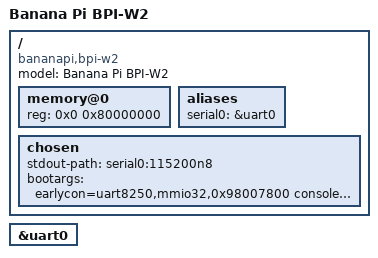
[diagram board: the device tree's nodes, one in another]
/*
 * Copyright (c) 2019 Nicolas Saenz Julienne
 *
 * SPDX-License-Identifier: (GPL-2.0+ OR MIT)
 */

/dts-v1/;

#include "rtd1296.dtsi"

/ {
	compatible = "bananapi,bpi-w2", "realtek,rtd1296";
	model = "Banana Pi BPI-W2";

	memory@0 {
		device_type = "memory";
		reg = <0x0 0x80000000>;
	};

	aliases {
		serial0 = &uart0;
	};

	chosen {
		stdout-path = "serial0:115200n8";
		bootargs = "earlycon=uart8250,mmio32,0x98007800 console=ttyS0,115200 loglevel=7";
	};
};

&uart0 {
	status = "okay";
};
